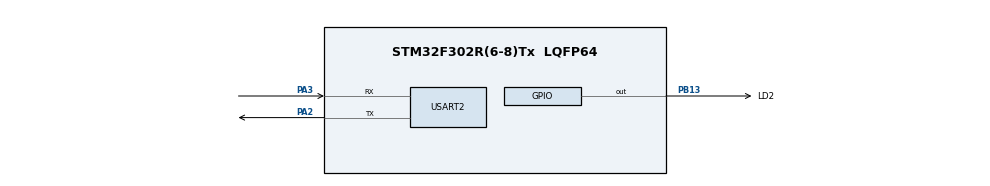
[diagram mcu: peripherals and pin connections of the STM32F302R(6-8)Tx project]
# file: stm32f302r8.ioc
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Mcu.Family=STM32F3
Mcu.Name=STM32F302R(6-8)Tx
Mcu.Package=LQFP64
NVIC.PriorityGroup=NVIC_PRIORITYGROUP_4
NVIC.USART2_IRQn=true\:0\:0\:false\:false\:true\:true\:true
PA2.Mode=Asynchronous
PA2.Signal=USART2_TX
PA3.Mode=Asynchronous
PA3.Signal=USART2_RX
PB13.GPIO_Label=LD2
PB13.Signal=GPIO_Output
PC14\ -\ OSC32_IN.Mode=LSE-External-Oscillator
PC14\ -\ OSC32_IN.Signal=RCC_OSC32_IN
PC15\ -\ OSC32_OUT.Mode=LSE-External-Oscillator
PC15\ -\ OSC32_OUT.Signal=RCC_OSC32_OUT
ProjectManager.HeapSize=0x200
ProjectManager.StackSize=0x400
ProjectManager.TargetToolchain=Other Toolchains (GPDSC)
RCC.AHBFreq_Value=64000000
RCC.APB1CLKDivider=RCC_HCLK_DIV2
RCC.APB1Freq_Value=32000000
RCC.APB1TimFreq_Value=64000000
RCC.APB2Freq_Value=64000000
RCC.APB2TimFreq_Value=64000000
RCC.CortexFreq_Value=64000000
RCC.HCLKFreq_Value=64000000
RCC.HSE_VALUE=8000000
RCC.HSI_VALUE=8000000
RCC.PLLMUL=RCC_PLL_MUL16
RCC.SYSCLKFreq_VALUE=64000000
RCC.SYSCLKSourceVirtual=RCC_SYSCLKSOURCE_PLLCLK
RCC.USBFreq_Value=64000000
USART2.VirtualMode-Asynchronous=VM_ASYNC
board=custom

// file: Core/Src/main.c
/* USER CODE BEGIN Header */
/**
  ******************************************************************************
  * @file           : main.c
  * @brief          : Main program body
  ******************************************************************************
  * @attention
  *
  * <h2><center>&copy; Copyright (c) 2019 STMicroelectronics.
  * All rights reserved.</center></h2>
  *
  * This software component is licensed by ST under BSD 3-Clause license,
  * the "License"; You may not use this file except in compliance with the
  * License. You may obtain a copy of the License at:
  *                        opensource.org/licenses/BSD-3-Clause
  *
  ******************************************************************************
  */
/* USER CODE END Header */

#include "main.h"

void SystemClock_Config(void);
static void MX_GPIO_Init(void);
static void MX_USART2_UART_Init(void);

int main(void)
{

  /* MCU Configuration--------------------------------------------------------*/

  /* Reset of all peripherals, Initializes the Flash interface and the Systick. */

  LL_APB2_GRP1_EnableClock(LL_APB2_GRP1_PERIPH_SYSCFG);
  LL_APB1_GRP1_EnableClock(LL_APB1_GRP1_PERIPH_PWR);

  NVIC_SetPriorityGrouping(NVIC_PRIORITYGROUP_4);

  /* System interrupt init*/

  /* Configure the system clock */
  SystemClock_Config();

  /* USER CODE BEGIN SysInit */
  SysTick_Config(SystemCoreClock/1000);
  /* USER CODE END SysInit */

  /* Initialize all configured peripherals */
  MX_GPIO_Init();
  MX_USART2_UART_Init();

  /* Infinite loop */
  while (1)
  {

  }
}

void SystemClock_Config(void)
{
  LL_FLASH_SetLatency(LL_FLASH_LATENCY_2);

   if(LL_FLASH_GetLatency() != LL_FLASH_LATENCY_2)
  {
  Error_Handler();
  }
  LL_RCC_HSI_Enable();

   /* Wait till HSI is ready */
  while(LL_RCC_HSI_IsReady() != 1)
  {

  }
  LL_RCC_HSI_SetCalibTrimming(16);
  LL_RCC_PLL_ConfigDomain_SYS(LL_RCC_PLLSOURCE_HSI_DIV_2, LL_RCC_PLL_MUL_16);
  LL_RCC_PLL_Enable();

   /* Wait till PLL is ready */
  while(LL_RCC_PLL_IsReady() != 1)
  {

  }
  LL_RCC_SetAHBPrescaler(LL_RCC_SYSCLK_DIV_1);
  LL_RCC_SetAPB1Prescaler(LL_RCC_APB1_DIV_2);
  LL_RCC_SetAPB2Prescaler(LL_RCC_APB1_DIV_1);
  LL_RCC_SetSysClkSource(LL_RCC_SYS_CLKSOURCE_PLL);

   /* Wait till System clock is ready */
  while(LL_RCC_GetSysClkSource() != LL_RCC_SYS_CLKSOURCE_STATUS_PLL)
  {

  }
  LL_Init1msTick(64000000);
  LL_SYSTICK_SetClkSource(LL_SYSTICK_CLKSOURCE_HCLK);
  LL_SetSystemCoreClock(64000000);
}

static void MX_USART2_UART_Init(void)
{

  LL_USART_InitTypeDef USART_InitStruct = {0};

  LL_GPIO_InitTypeDef GPIO_InitStruct = {0};

  /* Peripheral clock enable */
  LL_APB1_GRP1_EnableClock(LL_APB1_GRP1_PERIPH_USART2);

  LL_AHB1_GRP1_EnableClock(LL_AHB1_GRP1_PERIPH_GPIOA);
  /**USART2 GPIO Configuration
  PA2   ------> USART2_TX
  PA3   ------> USART2_RX
  */
  GPIO_InitStruct.Pin = LL_GPIO_PIN_2|LL_GPIO_PIN_3;
  GPIO_InitStruct.Mode = LL_GPIO_MODE_ALTERNATE;
  GPIO_InitStruct.Speed = LL_GPIO_SPEED_FREQ_HIGH;
  GPIO_InitStruct.OutputType = LL_GPIO_OUTPUT_PUSHPULL;
  GPIO_InitStruct.Pull = LL_GPIO_PULL_NO;
  GPIO_InitStruct.Alternate = LL_GPIO_AF_7;
  LL_GPIO_Init(GPIOA, &GPIO_InitStruct);

  /* USART2 interrupt Init */
  NVIC_SetPriority(USART2_IRQn, NVIC_EncodePriority(NVIC_GetPriorityGrouping(),0, 0));
  NVIC_EnableIRQ(USART2_IRQn);

  USART_InitStruct.BaudRate = 38400;
  USART_InitStruct.DataWidth = LL_USART_DATAWIDTH_8B;
  USART_InitStruct.StopBits = LL_USART_STOPBITS_1;
  USART_InitStruct.Parity = LL_USART_PARITY_NONE;
  USART_InitStruct.TransferDirection = LL_USART_DIRECTION_TX_RX;
  USART_InitStruct.HardwareFlowControl = LL_USART_HWCONTROL_NONE;
  USART_InitStruct.OverSampling = LL_USART_OVERSAMPLING_16;
  LL_USART_Init(USART2, &USART_InitStruct);
  LL_USART_DisableIT_CTS(USART2);
  LL_USART_ConfigAsyncMode(USART2);
  LL_USART_Enable(USART2);
  /* USER CODE BEGIN USART2_Init 2 */

  LL_USART_EnableIT_RXNE(USART2);

  /* USER CODE END USART2_Init 2 */

}

static void MX_GPIO_Init(void)
{
  LL_GPIO_InitTypeDef GPIO_InitStruct = {0};

  /* GPIO Ports Clock Enable */
  LL_AHB1_GRP1_EnableClock(LL_AHB1_GRP1_PERIPH_GPIOC);
  LL_AHB1_GRP1_EnableClock(LL_AHB1_GRP1_PERIPH_GPIOA);
  LL_AHB1_GRP1_EnableClock(LL_AHB1_GRP1_PERIPH_GPIOB);

  /**/
  LL_GPIO_ResetOutputPin(LD2_GPIO_Port, LD2_Pin);

  /**/
  GPIO_InitStruct.Pin = LD2_Pin;
  GPIO_InitStruct.Mode = LL_GPIO_MODE_OUTPUT;
  GPIO_InitStruct.Speed = LL_GPIO_SPEED_FREQ_LOW;
  GPIO_InitStruct.OutputType = LL_GPIO_OUTPUT_PUSHPULL;
  GPIO_InitStruct.Pull = LL_GPIO_PULL_NO;
  LL_GPIO_Init(LD2_GPIO_Port, &GPIO_InitStruct);

}

void Error_Handler(void)
{
}

/************************ (C) COPYRIGHT STMicroelectronics *****END OF FILE****/
